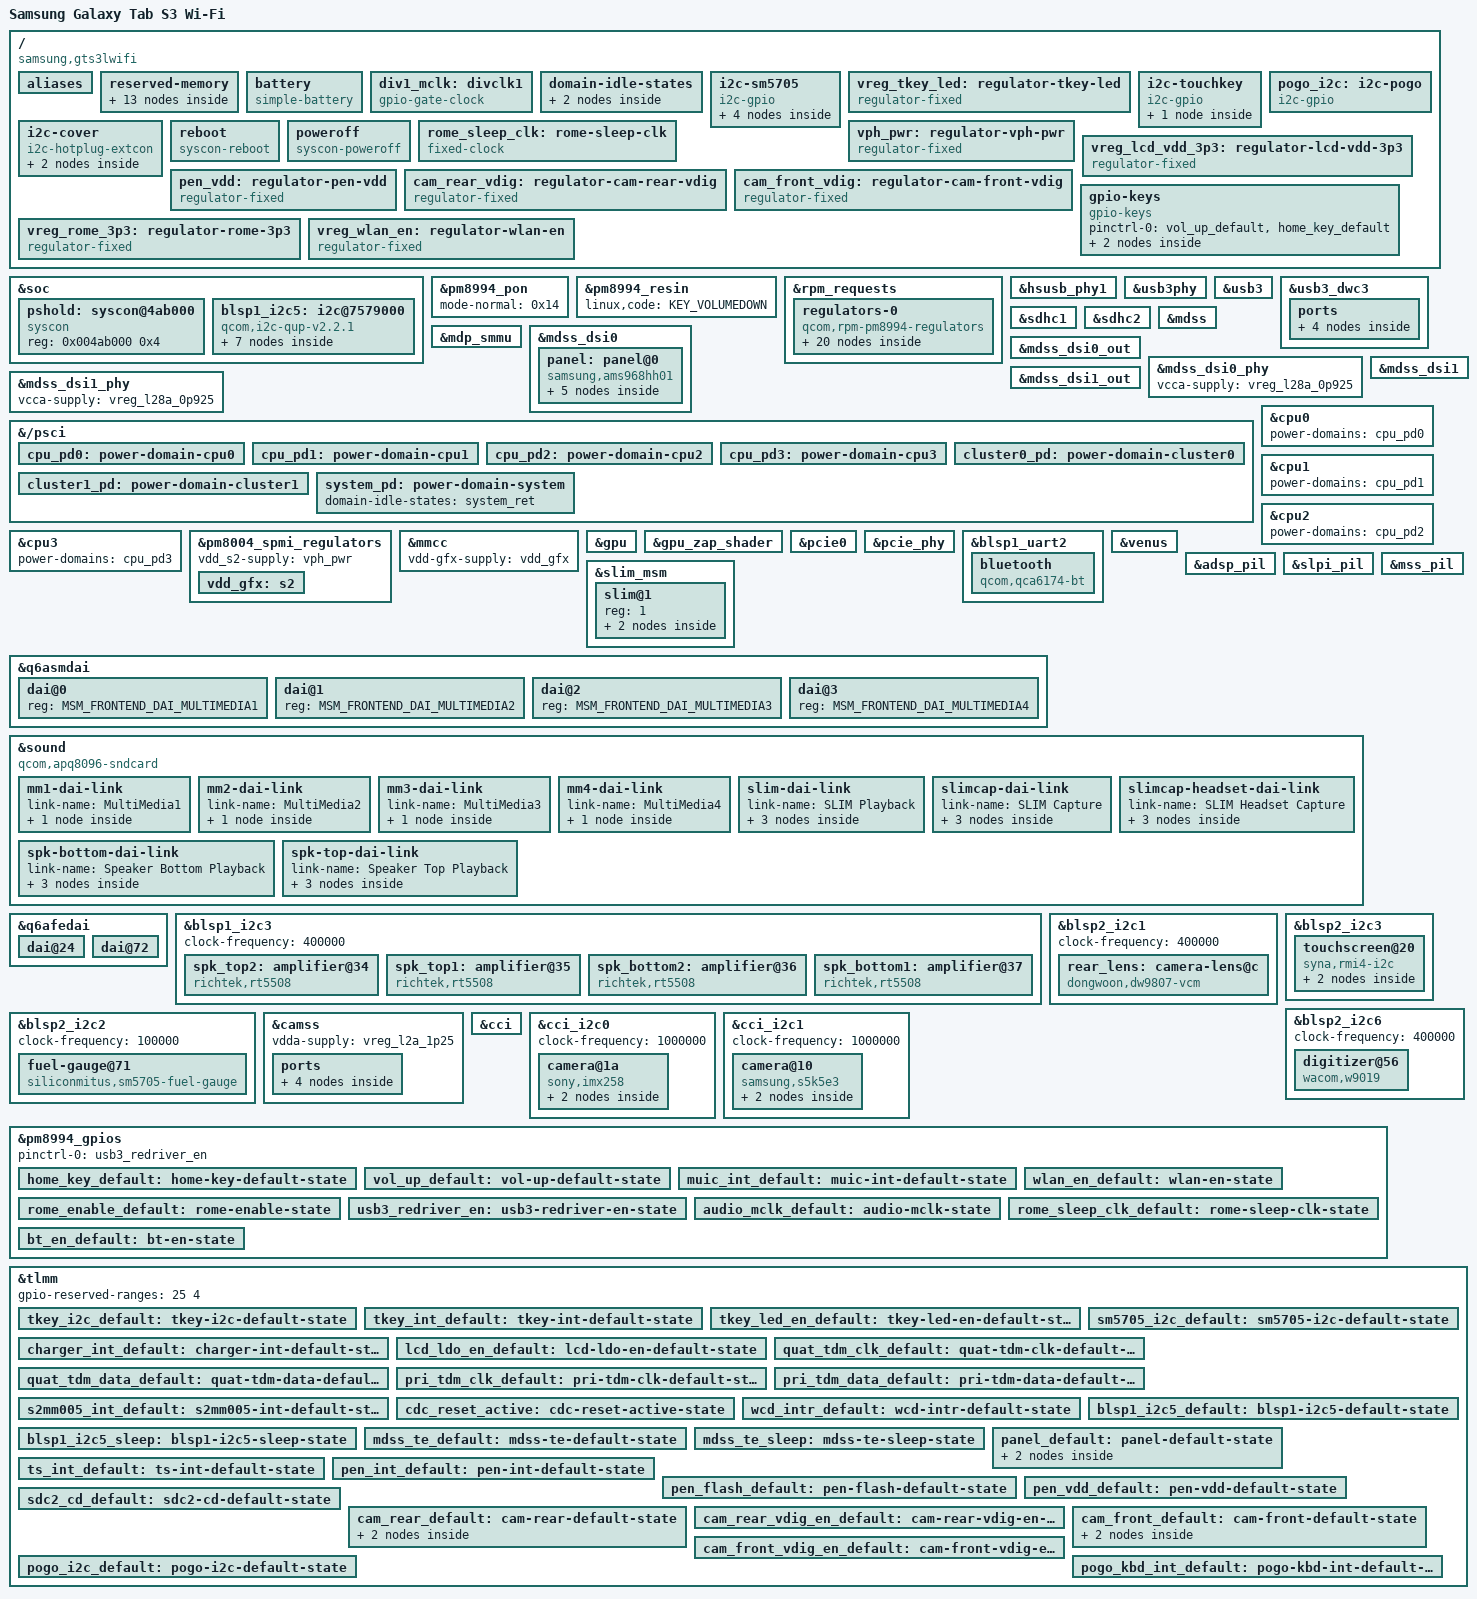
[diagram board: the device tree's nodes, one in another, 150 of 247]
// SPDX-License-Identifier: BSD-3-Clause
/*
 * Samsung Galaxy Tab S3 Wi-Fi (SM-T820), codename gts3lwifi, board rev 05
 *
 * SoC / PMIC set, from the live downstream DTB (qcom,pmic-id = <0x20009 0x1000c>):
 *   APQ8096 (msm-id 291) + PM8994 + PM8004. No PMI8994. No cellular modem,
 *   but the modem DSP is there and runs a GNSS-only image.
 * Internal storage: eMMC on SDHC1 (cmdline: androidboot.bootdevice=7464900.sdhci).
 *   UFS silicon is present but unpopulated; ufshc/ufsphy stay disabled.
 *
 * Working: eMMC, microSD, USB peripheral, host and OTG (USB 3.0), reboot
 * and power-off, display (AMS968HH01 dual-DSI command-mode panel), GPU,
 * touch, S-Pen, Volume and Home keys, Wi-Fi and Bluetooth (QCA6174), Venus,
 * audio (ADSP + WCD9335: headphones and microphones; four RT5508 speaker
 * amplifiers), SM5705 fuel gauge, charger, MUIC and flash LED (torch),
 * S2MM005 USB Type-C/PD (sink up to 9 V, source), accelerometer, gyroscope
 * and magnetometer (through the SLPI sensor core), CPU/cluster/system idle,
 * both cameras, the Book Cover Keyboard (hot-plugged through the MUIC),
 * GNSS (on the modem DSP). The panel's temperature input has a test DT; the
 * cover's hall sensor is not here yet.
 *
 * GPU zap shader, Venus, ADSP, SLPI and modem DSP firmware are
 * Samsung-signed and come from the device (apnhlos and modem partitions),
 * under
 * qcom/msm8996/samsung/gts3/; the device package's gts3-firmware copies
 * them, and the sensor registry from the efs partition, on first boot.
 *
 * The LTE model (SM-T825) uses this file too: msm8996-samsung-gts3llte.dts
 * includes it and changes the SoC ID, the modem memory and the pins it may
 * not touch. One kernel and one device package boot both models.
 *
 * Sources (all cross-checked against the live DTB with phandles resolved):
 *   downstream arch/arm64/boot/dts/samsung/msm8996-sec-gts3lwifi-r05.dts{,i}
 *   downstream arch/arm64/boot/dts/samsung/msm8996-pinctrl-sec-gts3lwifi-r05.dtsi
 *   downstream arch/arm64/boot/dts/samsung/msm8996-sec-common.dtsi
 *   downstream arch/arm64/boot/dts/samsung/msm8996-sm5705.dtsi
 *   downstream arch/arm64/boot/dts/qcom/msm8996-pm.dtsi (idle StateIDs)
 */

/dts-v1/;

#include <dt-bindings/clock/qcom,dsi-phy-28nm.h>
#include <dt-bindings/gpio/gpio.h>
#include <dt-bindings/input/input.h>
#include <dt-bindings/interrupt-controller/irq.h>
#include <dt-bindings/leds/common.h>
#include <dt-bindings/pinctrl/qcom,pmic-gpio.h>
#include <dt-bindings/sound/qcom,q6afe.h>
#include <dt-bindings/sound/qcom,q6asm.h>
#include <dt-bindings/sound/qcom,wcd9335.h>
#include <dt-bindings/usb/pd.h>
#include "msm8996.dtsi"
#include "pm8994.dtsi"
#include "pm8004.dtsi"

/*
 * The firmware regions get the stock SM-T820 layout (reserved-memory
 * below): the modem image needs the whole stock modem carve-out, which is
 * larger than msm8996.dtsi's mpss_mem, so the regions after it move.
 */
/delete-node/ &mpss_mem;
/delete-node/ &slpi_mem;
/delete-node/ &adsp_mem;
/delete-node/ &gpu_mem;
/delete-node/ &venus_mem;
/delete-node/ &mba_mem;

/ {
	model = "Samsung Galaxy Tab S3 Wi-Fi";
	compatible = "samsung,gts3lwifi", "qcom,apq8096";
	chassis-type = "tablet";

	/*
	 * DTB-selection IDs (documented in arm/qcom.yaml). lk2nd, like the
	 * stock bootloader, picks the appended DTB whose msm-id and board-id
	 * match the tablet: msm-id 291 (APQ8096) is the SM-T820, 246 (MSM8996)
	 * the SM-T825 (msm8996-samsung-gts3llte.dts). Stock ships one DT per
	 * board revision, Rev00/02/04/05 as board-id <8 0>, <8 2>, <8 4>,
	 * <8 5>; list them all, or lk2nd finds no match on a tablet of another
	 * revision and refuses the image ("dtb not found").
	 */
	qcom,msm-id = <291 0x30001>;
	qcom,board-id = <8 0>, <8 2>, <8 4>, <8 5>;

	aliases {
		mmc0 = &sdhc1;
		mmc1 = &sdhc2;
	};

	/*
	 * No memory@ node on purpose: msm8996.dtsi carries the placeholder
	 * and lk2nd rewrites it from the DDR partition table. The live DTB
	 * shows 0x80000000 + 2 GiB and 0x100000000 + 0x7e5e0000, i.e. 4 GiB
	 * with a hole - hardcoding a flat 4 GiB at 0x80000000 overshoots.
	 */

	/*
	 * Fixed regions from the downstream tree that msm8996.dtsi does not
	 * already cover, and the firmware regions with the stock layout.
	 * hyp/xbl/smem/tz (0x85800000-0x88800000) in msm8996.dtsi are subsets
	 * of the downstream removed carve-out, so they are kept as they are.
	 */
	reserved-memory {
		/* Downstream ss_plog@84700000 */
		memory@84700000 {
			reg = <0x0 0x84700000 0x0 0x400000>;
			no-map;
		};

		/* Same slot and layout as downstream ramoops@84B00000 */
		ramoops@84b00000 {
			compatible = "ramoops";
			reg = <0x0 0x84b00000 0x0 0x100000>;
			record-size = <0x40000>;
			console-size = <0x40000>;
			ftrace-size = <0x40000>;
			pmsg-size = <0x40000>;
		};

		/* Downstream lk_region@0 */
		memory@84c00000 {
			reg = <0x0 0x84c00000 0x0 0x400000>;
			no-map;
		};

		/*
		 * Samsung sec_debug: sec_dbg=0x1ff000@0x85000000 and
		 * sec_log=0x200000@0x85200000 on the downstream cmdline.
		 * S-Boot reads this back in upload mode, keep it untouched.
		 */
		memory@85000000 {
			reg = <0x0 0x85000000 0x0 0x400000>;
			no-map;
		};

		/*
		 * Firmware regions, as the stock kernel places them on the
		 * SM-T820 (all of these images are relocatable). The modem
		 * image spans 0x6c00000 bytes from its lowest segment to the end
		 * of its last: the downstream modem_mem carve-out
		 * (msm8996-sec-common.dtsi), where stock loads it.
		 * qcom_q6v5_mss refuses a segment that ends past mpss_mem, and
		 * msm8996.dtsi's is 0x6200000. SLPI, ADSP (its segments span
		 * 0x2100000 bytes), the A530 zap shader and Venus then fill the
		 * downstream peripheral_region (0x8f400000-0x92500000), and the
		 * MBA, which stock allocates dynamically, goes right after it.
		 */
		mpss_mem: mpss@88800000 {
			reg = <0x0 0x88800000 0x0 0x6c00000>;
			no-map;
		};

		slpi_mem: slpi@8f400000 {
			reg = <0x0 0x8f400000 0x0 0xa00000>;
			no-map;
		};

		adsp_mem: adsp@8fe00000 {
			reg = <0x0 0x8fe00000 0x0 0x2100000>;
			no-map;
		};

		gpu_mem: gpu@91f00000 {
			compatible = "shared-dma-pool";
			reg = <0x0 0x91f00000 0x0 0x100000>;
			no-map;
		};

		venus_mem: venus@92000000 {
			reg = <0x0 0x92000000 0x0 0x500000>;
			no-map;
		};

		mba_mem: mba@92500000 {
			reg = <0x0 0x92500000 0x0 0x200000>;
			no-map;
		};

		/*
		 * The bootloader framebuffer (downstream cont_splash_mem,
		 * 0x9a400000, 28 MiB) is not reserved here: lk2nd adds its own
		 * reservation for it when lk2nd.pass-simplefb is used, and the
		 * two would overlap.
		 */

		/* Samsung TIMA (KNOX EL2), downstream tima_region@9C000000 */
		memory@9c000000 {
			reg = <0x0 0x9c000000 0x0 0x200000>;
			no-map;
		};

		/* Samsung RKP (KNOX EL2), downstream rkp_region@0x9C200000 */
		memory@9c200000 {
			reg = <0x0 0x9c200000 0x0 0xf00000>;
			no-map;
		};

		/* Pool handed to TrustZone, downstream qseecom_mem */
		memory@fec00000 {
			reg = <0x0 0xfec00000 0x0 0x1400000>;
			no-map;
		};
	};

	/*
	 * EB-BT825ABE, 6000 mAh, 3.85 V. Stock charges to 4.30 V
	 * (battery,chg_float_voltage), tops off at 300 mA, powers off
	 * around 3.4 V (battery0,tem_poff) and stops charging outside
	 * 0-50 C (battery,temp_{low,high}_threshold_normal).
	 */
	battery: battery {
		compatible = "simple-battery";
		device-chemistry = "lithium-ion";
		charge-full-design-microamp-hours = <6000000>;
		energy-full-design-microwatt-hours = <23100000>;
		voltage-min-design-microvolt = <3400000>;
		voltage-max-design-microvolt = <4300000>;
		constant-charge-voltage-max-microvolt = <4300000>;
		charge-term-current-microamp = <300000>;
		alert-celsius = <0 50>;
	};

	/* WCD9335 MCLK, 9.6 MHz: RPM div_clk1 out on PM8994 GPIO 15 */
	div1_mclk: divclk1 {
		compatible = "gpio-gate-clock";
		clocks = <&rpmcc RPM_SMD_DIV_CLK1>;
		#clock-cells = <0>;
		enable-gpios = <&pm8994_gpios 15 GPIO_ACTIVE_HIGH>;
		pinctrl-names = "default";
		pinctrl-0 = <&audio_mclk_default>;
	};

	/*
	 * Cluster and system idle, used through the PSCI power domains
	 * below. The firmware composes StateIDs the OSI way, like the
	 * downstream lpm-levels: power-down bit 30, affinity level at bit
	 * 24, system mode at bit 8, cluster mode at bit 4, CPU mode at bit 0.
	 * It grants L2 GDHS and system retention to the last CPU going down,
	 * with the CPUs in mode 4 without the power-down bit. It refuses the
	 * CPU power-down state (0x40000004, NOT_SUPPORTED), and with it L2
	 * power collapse (0x41000044, always DENIED). Latencies are on the
	 * safe side; downstream lists 90 and 350 us.
	 */
	domain-idle-states {
		cluster_gdhs: cluster-gdhs {
			compatible = "domain-idle-state";
			arm,psci-suspend-param = <0x01000034>;
			entry-latency-us = <200>;
			exit-latency-us = <300>;
			min-residency-us = <1000>;
		};

		system_ret: system-ret {
			compatible = "domain-idle-state";
			arm,psci-suspend-param = <0x02002334>;
			entry-latency-us = <400>;
			exit-latency-us = <700>;
			min-residency-us = <3000>;
		};
	};

	/*
	 * SM5705 charger and MUIC. Downstream bit-bangs this bus on TLMM 33
	 * (SDA) / 32 (SCL), which are HDMI DDC pins, not a BLSP pair. The
	 * fuel gauge of the same chip is on its own bus, see &blsp2_i2c2.
	 */
	i2c-sm5705 {
		compatible = "i2c-gpio";
		sda-gpios = <&tlmm 33 (GPIO_ACTIVE_HIGH | GPIO_OPEN_DRAIN)>;
		scl-gpios = <&tlmm 32 (GPIO_ACTIVE_HIGH | GPIO_OPEN_DRAIN)>;
		i2c-gpio,delay-us = <2>;
		pinctrl-names = "default";
		pinctrl-0 = <&sm5705_i2c_default>;
		#address-cells = <1>;
		#size-cells = <0>;

		/* USB charger type (BC1.2) */
		muic: extcon@25 {
			compatible = "siliconmitus,sm5705-muic";
			reg = <0x25>;
			interrupts-extended = <&pm8994_gpios 4 IRQ_TYPE_LEVEL_LOW>;
			pinctrl-names = "default";
			pinctrl-0 = <&muic_int_default>;
		};

		/*
		 * Charger and flash LED. Charging enable is PM8994 GPIO 13,
		 * active low; the bootloader leaves it low. Without a driver
		 * the charger keeps a 4.38 V charge voltage; the driver applies
		 * the battery's 4.30 V.
		 */
		charger: charger@49 {
			compatible = "siliconmitus,sm5705-charger";
			reg = <0x49>;
			interrupts-extended = <&tlmm 38 IRQ_TYPE_LEVEL_LOW>;
			pinctrl-names = "default";
			pinctrl-0 = <&charger_int_default>;
			monitored-battery = <&battery>;
			extcon = <&muic>;
			power-supplies = <&typec>;

			/*
			 * Rear camera flash on FLED1, as a torch over I2C. Stock
			 * drives it through TLMM 11 (torch) / 12 (flash) instead;
			 * they stay low. 180 mA is stock's camera torch current.
			 */
			led {
				function = LED_FUNCTION_TORCH;
				color = <LED_COLOR_ID_WHITE>;
				led-max-microamp = <180000>;
			};

			/* the boost onto VBUS, for USB OTG */
			otg_vbus: usb-otg-vbus {
				regulator-name = "usb_otg_vbus";
			};
		};
	};

	/*
	 * Recent and Back keys (downstream i2c@22, tc305k@20): the controller
	 * runs from L19, and TLMM 118 switches the supply of the key LEDs.
	 */
	vreg_tkey_led: regulator-tkey-led {
		compatible = "regulator-fixed";
		regulator-name = "vreg_tkey_led";
		gpio = <&tlmm 118 GPIO_ACTIVE_HIGH>;
		enable-active-high;
		pinctrl-0 = <&tkey_led_en_default>;
		pinctrl-names = "default";
	};

	i2c-touchkey {
		compatible = "i2c-gpio";
		sda-gpios = <&tlmm 21 (GPIO_ACTIVE_HIGH | GPIO_OPEN_DRAIN)>;
		scl-gpios = <&tlmm 22 (GPIO_ACTIVE_HIGH | GPIO_OPEN_DRAIN)>;
		pinctrl-0 = <&tkey_i2c_default>;
		pinctrl-names = "default";
		#address-cells = <1>;
		#size-cells = <0>;

		touchkey@20 {
			compatible = "coreriver,tc305k-touchkey";
			reg = <0x20>;
			interrupts-extended = <&tlmm 64 IRQ_TYPE_LEVEL_LOW>;
			vcc-supply = <&vreg_l19a_2p2>;
			vdd-supply = <&vreg_tkey_led>;
			linux,keycodes = <KEY_APPSELECT KEY_BACK>;
			pinctrl-0 = <&tkey_int_default>;
			pinctrl-names = "default";
		};
	};

	/* Book Cover Keyboard (EJ-FT820) on the pogo pins */
	pogo_i2c: i2c-pogo {
		compatible = "i2c-gpio";
		sda-gpios = <&tlmm 2 (GPIO_ACTIVE_HIGH | GPIO_OPEN_DRAIN)>;
		scl-gpios = <&tlmm 3 (GPIO_ACTIVE_HIGH | GPIO_OPEN_DRAIN)>;
		i2c-gpio,delay-us = <2>;
		pinctrl-0 = <&pogo_i2c_default>;
		pinctrl-names = "default";
		#address-cells = <1>;
		#size-cells = <0>;
	};

	/*
	 * The keyboard's controller is only there while the cover is
	 * attached, which the MUIC reports as a dock (49.9 kOhm on the ID
	 * pin, ADC_KEYBOARDDOCK in Samsung's muic.h).
	 */
	i2c-cover {
		compatible = "i2c-hotplug-extcon";
		extcon = <&muic>;
		i2c-parent = <&pogo_i2c>;
		#address-cells = <1>;
		#size-cells = <0>;

		keyboard@40 {
			compatible = "st,stmpe1801";
			reg = <0x40>;
			/* stmpe_probe() only looks for "interrupts" */
			interrupt-parent = <&tlmm>;
			interrupts = <54 IRQ_TYPE_LEVEL_LOW>;
			pinctrl-0 = <&pogo_kbd_int_default>;
			pinctrl-names = "default";
			vcc-supply = <&vreg_l6a_1p8>;
			/* a key press wakes the tablet, while the cover is on */
			wakeup-source;

			keyboard-controller {
				compatible = "st,stmpe-keypad";
				debounce-interval = <10>;
				st,scan-count = <3>;
				keypad,num-rows = <8>;
				keypad,num-columns = <10>;
				linux,keymap = <
					MATRIX_KEY(0, 2, KEY_Z)
					MATRIX_KEY(0, 3, KEY_102ND)
					MATRIX_KEY(0, 4, KEY_V)
					MATRIX_KEY(0, 5, KEY_M)
					MATRIX_KEY(0, 6, KEY_DOWN)
					MATRIX_KEY(0, 8, KEY_SPACE)
					MATRIX_KEY(0, 9, KEY_UP)
					MATRIX_KEY(1, 0, KEY_ONSCREEN_KEYBOARD)
					MATRIX_KEY(1, 1, KEY_LEFTMETA)
					MATRIX_KEY(1, 2, KEY_A)
					MATRIX_KEY(1, 3, KEY_X)
					MATRIX_KEY(1, 4, KEY_B)
					MATRIX_KEY(1, 5, KEY_N)
					MATRIX_KEY(1, 6, KEY_COMMA)
					MATRIX_KEY(1, 7, KEY_DOT)
					MATRIX_KEY(1, 8, KEY_SLASH)
					MATRIX_KEY(1, 9, KEY_RIGHTBRACE)
					MATRIX_KEY(2, 1, KEY_HANGEUL)
					MATRIX_KEY(2, 2, KEY_Q)
					MATRIX_KEY(2, 3, KEY_S)
					MATRIX_KEY(2, 4, KEY_F)
					MATRIX_KEY(2, 5, KEY_J)
					MATRIX_KEY(2, 6, KEY_K)
					MATRIX_KEY(2, 7, KEY_L)
					MATRIX_KEY(2, 8, KEY_SEMICOLON)
					MATRIX_KEY(2, 9, KEY_ENTER)
					MATRIX_KEY(3, 1, KEY_LEFTALT)
					MATRIX_KEY(3, 2, KEY_TAB)
					MATRIX_KEY(3, 3, KEY_W)
					MATRIX_KEY(3, 4, KEY_G)
					MATRIX_KEY(3, 5, KEY_H)
					MATRIX_KEY(3, 6, KEY_I)
					MATRIX_KEY(3, 7, KEY_APOSTROPHE)
					MATRIX_KEY(3, 8, KEY_P)
					MATRIX_KEY(3, 9, KEY_BACKSLASH)
					MATRIX_KEY(4, 0, KEY_CAPSLOCK)
					MATRIX_KEY(4, 1, KEY_RIGHTALT)
					MATRIX_KEY(4, 2, KEY_1)
					MATRIX_KEY(4, 3, KEY_2)
					MATRIX_KEY(4, 4, KEY_R)
					MATRIX_KEY(4, 5, KEY_U)
					MATRIX_KEY(4, 6, KEY_8)
					MATRIX_KEY(4, 7, KEY_O)
					MATRIX_KEY(4, 8, KEY_0)
					MATRIX_KEY(4, 9, KEY_BACKSLASH)
					MATRIX_KEY(5, 1, KEY_LEFTCTRL)
					MATRIX_KEY(5, 2, KEY_GRAVE)
					MATRIX_KEY(5, 3, KEY_RIGHT)
					MATRIX_KEY(5, 4, KEY_T)
					MATRIX_KEY(5, 5, KEY_Y)
					MATRIX_KEY(5, 7, KEY_LEFTBRACE)
					MATRIX_KEY(5, 8, KEY_BACKSPACE)
					MATRIX_KEY(5, 9, KEY_MINUS)
					MATRIX_KEY(6, 0, KEY_RIGHTSHIFT)
					MATRIX_KEY(6, 1, KEY_LEFT)
					MATRIX_KEY(6, 2, KEY_D)
					MATRIX_KEY(6, 3, KEY_C)
					MATRIX_KEY(6, 4, KEY_4)
					MATRIX_KEY(6, 5, KEY_7)
					MATRIX_KEY(6, 7, KEY_9)
					MATRIX_KEY(6, 8, KEY_3)
					MATRIX_KEY(6, 9, KEY_E)
					MATRIX_KEY(7, 0, KEY_LEFTSHIFT)
					MATRIX_KEY(7, 4, KEY_5)
					MATRIX_KEY(7, 6, KEY_6)
					MATRIX_KEY(7, 7, KEY_EQUAL)
				>;
			};
		};
	};

	/*
	 * Restart. Samsung's TrustZone never returns from PSCI SYSTEM_RESET:
	 * the CPU stays stuck in the call, and about a minute later a secure
	 * watchdog leaves the tablet in a state that needs a forced restart.
	 * The vendor kernel never uses PSCI for this; it drops PS_HOLD
	 * (MPM2 PS_HOLD, 0x004ab000 bit 0, writable from Linux) and the PMIC
	 * resets. syscon-reboot does the same and, at its default priority
	 * (192), runs before the PSCI handler (129). pm8941-pwrkey programs
	 * the PMIC PS_HOLD reset type (hard reset) on a normal reboot.
	 */
	reboot {
		compatible = "syscon-reboot";
		regmap = <&pshold>;
		offset = <0x0>;
		mask = <0x1>;
		value = <0x0>;
	};

	/*
	 * Power-off: PSCI SYSTEM_OFF returns without doing anything in
	 * Samsung's TrustZone, and the kernel then runs on with the other CPUs
	 * stopped. Drop PS_HOLD as for restart; pm8941-pwrkey has set the PMIC
	 * PS_HOLD reset type to shutdown by then. Runs after the PSCI handler.
	 */
	poweroff {
		compatible = "syscon-poweroff";
		regmap = <&pshold>;
		offset = <0x0>;
		mask = <0x1>;
		value = <0x0>;
	};

	/* QCA6174 sleep clock: PM8994 GPIO 18 function 2, see &pm8994_gpios */
	rome_sleep_clk: rome-sleep-clk {
		compatible = "fixed-clock";
		#clock-cells = <0>;
		clock-frequency = <32768>;
		clock-output-names = "rome_sleep_clk";
	};

	/* Battery / charger system rail, root of every PM8994 supply below */
	vph_pwr: regulator-vph-pwr {
		compatible = "regulator-fixed";
		regulator-name = "vph_pwr";
		regulator-min-microvolt = <3800000>;
		regulator-max-microvolt = <3800000>;
		regulator-always-on;
		regulator-boot-on;
	};

	/*
	 * SM57xx rails
	 * ------------
	 * None on this board feed USB, eMMC or the panel:
	 *  - SM5703 (msm8996-sm5703.dtsi) is only included by gts2llte,
	 *    never by any gts3lwifi/gts3llte revision.
	 *  - SM5705 (msm8996-sm5705.dtsi) is charger + MUIC + fuel gauge +
	 *    flash LED. The downstream defconfig does not set
	 *    CONFIG_REGULATOR_SM5705, no such driver exists in that tree,
	 *    and no *-supply anywhere resolves to an SM5705 node.
	 *  - USB PHYs: PM8994 L28 / L12 / L24. eMMC: PM8994 L20 / S4.
	 *    Panel VDD 3.3 V: external LDO gated by LCD_LDO_EN (TLMM 46),
	 *    modelled downstream as the fake regulator "ssreg-vdd".
	 * The only non-PMIC rail that therefore needs a stub is that LDO.
	 */
	vreg_lcd_vdd_3p3: regulator-lcd-vdd-3p3 {
		compatible = "regulator-fixed";
		regulator-name = "vreg_lcd_vdd_3p3";
		regulator-min-microvolt = <3300000>;
		regulator-max-microvolt = <3300000>;
		gpio = <&tlmm 46 GPIO_ACTIVE_HIGH>;
		enable-active-high;
		regulator-boot-on;
		regulator-always-on;
		vin-supply = <&vph_pwr>;
		pinctrl-names = "default";
		pinctrl-0 = <&lcd_ldo_en_default>;
	};

	/* S-Pen digitizer 3.3 V, a switch on TLMM 126 (downstream wacom@56) */
	pen_vdd: regulator-pen-vdd {
		compatible = "regulator-fixed";
		regulator-name = "pen_vdd_3p3";
		regulator-min-microvolt = <3300000>;
		regulator-max-microvolt = <3300000>;
		gpio = <&tlmm 126 GPIO_ACTIVE_HIGH>;
		enable-active-high;
		regulator-boot-on;
		pinctrl-names = "default";
		pinctrl-0 = <&pen_vdd_default>;
	};

	/*
	 * Camera core supplies: switched regulators fed from S3, enabled by
	 * CAM_CORE_EN (rear, TLMM 9) and CAM_VDIG (front, TLMM 8) in the
	 * downstream camera@0 and camera@2 nodes. Their output voltage is
	 * not documented downstream; 1.2 V is what both sensors take.
	 */
	cam_rear_vdig: regulator-cam-rear-vdig {
		compatible = "regulator-fixed";
		regulator-name = "cam_rear_vdig_1p2";
		regulator-min-microvolt = <1200000>;
		regulator-max-microvolt = <1200000>;
		gpio = <&tlmm 9 GPIO_ACTIVE_HIGH>;
		enable-active-high;
		startup-delay-us = <1000>;
		vin-supply = <&vreg_s3a_1p3>;
		pinctrl-names = "default";
		pinctrl-0 = <&cam_rear_vdig_en_default>;
	};

	cam_front_vdig: regulator-cam-front-vdig {
		compatible = "regulator-fixed";
		regulator-name = "cam_front_vdig_1p2";
		regulator-min-microvolt = <1200000>;
		regulator-max-microvolt = <1200000>;
		gpio = <&tlmm 8 GPIO_ACTIVE_HIGH>;
		enable-active-high;
		startup-delay-us = <1000>;
		vin-supply = <&vreg_s3a_1p3>;
		pinctrl-names = "default";
		pinctrl-0 = <&cam_front_vdig_en_default>;
	};

	/*
	 * Volume Up and Home (downstream gpio_keys in msm8996-sec-common.dtsi:
	 * PM8994 GPIO 3 and 2, active low, 15 ms debounce, Home a wakeup
	 * source). Volume Down is the PON RESIN input below, Power the PON
	 * power key. Home keeps the stock KEY_HOMEPAGE, as other Samsung DTs
	 * upstream do. The cover's hall sensor (stock hall_flip, PM8994
	 * GPIO 7) is left out until suspend is settled: logind suspends on
	 * SW_LID.
	 */
	gpio-keys {
		compatible = "gpio-keys";
		pinctrl-0 = <&vol_up_default>, <&home_key_default>;
		pinctrl-names = "default";

		key-volume-up {
			label = "Volume Up";
			gpios = <&pm8994_gpios 3 GPIO_ACTIVE_LOW>;
			linux,code = <KEY_VOLUMEUP>;
			debounce-interval = <15>;
		};

		key-home {
			label = "Home";
			gpios = <&pm8994_gpios 2 GPIO_ACTIVE_LOW>;
			linux,code = <KEY_HOMEPAGE>;
			wakeup-source;
			debounce-interval = <15>;
		};
	};

	/*
	 * QCA6174 ("Rome") Wi-Fi/BT power, from the downstream qcom,cnss
	 * node (cnss_wlan_en_vreg / rome_vreg), wired like the Xiaomi MSM8996
	 * boards: PM8994 GPIO 9 enables the 3.3 V supply, GPIO 8 is WLAN_EN.
	 *
	 * BT_EN (PM8994 GPIO 19) must be low while the 3.3 V rail comes up.
	 * The bootloader leaves it high; if the rail rises like that, Rome
	 * turns on its PCIe receiver after PERST# but never transmits (the
	 * root port sits in Polling.Compliance). So the 3.3 V regulator is
	 * not always-on: it starts off at probe, stays off for
	 * off-on-delay-us with BT_EN held low, and the PCIe driver switches
	 * it on through the WLAN_EN regulator.
	 */
	vreg_rome_3p3: regulator-rome-3p3 {
		compatible = "regulator-fixed";
		regulator-name = "vreg_rome_3p3";
		regulator-min-microvolt = <3300000>;
		regulator-max-microvolt = <3300000>;
		startup-delay-us = <4000>;
		off-on-delay-us = <1000000>;
		vin-supply = <&vph_pwr>;

		gpio = <&pm8994_gpios 9 GPIO_ACTIVE_HIGH>;
		enable-active-high;
		pinctrl-names = "default";
		pinctrl-0 = <&rome_enable_default>, <&bt_en_default>,
			    <&rome_sleep_clk_default>;
	};

	vreg_wlan_en: regulator-wlan-en {
		compatible = "regulator-fixed";
		regulator-name = "vreg_wlan_en";
		regulator-min-microvolt = <1800000>;
		regulator-max-microvolt = <1800000>;
		startup-delay-us = <70000>;
		vin-supply = <&vreg_rome_3p3>;

		gpio = <&pm8994_gpios 8 GPIO_ACTIVE_HIGH>;
		enable-active-high;
		pinctrl-names = "default";
		pinctrl-0 = <&wlan_en_default>;
	};
};

&soc {
	pshold: syscon@4ab000 {
		compatible = "syscon";
		reg = <0x004ab000 0x4>;
	};

	/*
	 * BLSP1 QUP5 I2C (TLMM 83 SDA, 84 SCL, downstream i2c_5), for the
	 * Type-C controller. msm8996.dtsi has no node for it; this one follows
	 * blsp1_i2c3/blsp1_i2c6 (QUP n: GIC SPI 94 + n, BAM channels 10 + 2n).
	 */
	blsp1_i2c5: i2c@7579000 {
		compatible = "qcom,i2c-qup-v2.2.1";
		reg = <0x07579000 0x1000>;
		interrupts = <GIC_SPI 99 IRQ_TYPE_LEVEL_HIGH>;
		clocks = <&gcc GCC_BLSP1_QUP5_I2C_APPS_CLK>,
			 <&gcc GCC_BLSP1_AHB_CLK>;
		clock-names = "core", "iface";
		pinctrl-names = "default", "sleep";
		pinctrl-0 = <&blsp1_i2c5_default>;
		pinctrl-1 = <&blsp1_i2c5_sleep>;
		dmas = <&blsp1_dma 20>, <&blsp1_dma 21>;
		dma-names = "tx", "rx";
		clock-frequency = <100000>;
		#address-cells = <1>;
		#size-cells = <0>;

		/*
		 * Samsung S2MM005 USB Type-C and PD controller. Its firmware
		 * negotiates the PD contract by itself; the charger takes its
		 * input limit from this supply too. As a source it needs the
		 * charger's boost for VBUS. Interrupt: open drain, low while
		 * an event is pending, pulled up on the board.
		 */
		typec: typec@33 {
			compatible = "samsung,s2mm005";
			reg = <0x33>;
			interrupts-extended = <&tlmm 73 IRQ_TYPE_LEVEL_LOW>;
			pinctrl-0 = <&s2mm005_int_default>;
			pinctrl-names = "default";

			connector {
				compatible = "usb-c-connector";
				label = "USB-C";
				power-role = "dual";
				data-role = "dual";
				vbus-supply = <&otg_vbus>;
				/*
				 * 5 V, or 9 V at the input limit Samsung uses
				 * for its 15 W chargers
				 */
				sink-pdos = <PDO_FIXED(5000, 3000,
						       PDO_FIXED_DUAL_ROLE |
						       PDO_FIXED_USB_COMM |
						       PDO_FIXED_DATA_SWAP)
					     PDO_FIXED(9000, 1650, 0)>;
				op-sink-microwatt = <15000000>;

				ports {
					#address-cells = <1>;
					#size-cells = <0>;

					port@0 {
						reg = <0>;

						typec_hs: endpoint {
							remote-endpoint = <&usb3_dwc3_hs>;
						};
					};

					port@1 {
						reg = <1>;

						typec_ss: endpoint {
							remote-endpoint = <&usb3_dwc3_ss>;
						};
					};
				};
			};
		};
	};
};

/*
 * Restart reasons as Samsung's bootloader reads them (vendor
 * PON_RESTART_REASON_*, stored in the PON spare register shifted by 2).
 * bootloader (0x02) and recovery (0x01) already match pm8994.dtsi;
 * NORMALBOOT (0x14) is what the vendor kernel writes on a plain reboot.
 */
&pm8994_pon {
	mode-normal = <0x14>;
};

/* Volume Down (downstream qcom,pon_2) */
&pm8994_resin {
	linux,code = <KEY_VOLUMEDOWN>;
	status = "okay";
};

/*
 * PM8994 rails via RPM. Only the rails consumed below are declared; the
 * parent-supply map follows apq8096-db820c.dts (PM8994 + no PMI8994 boost
 * bypass here, so the battery-fed LDO groups hang off vph_pwr directly).
 * Voltages match the downstream msm8996-regulator.dtsi / live DTB.
 */
&rpm_requests {
	regulators-0 {
		compatible = "qcom,rpm-pm8994-regulators";

		vdd_s1-supply = <&vph_pwr>;
		vdd_s2-supply = <&vph_pwr>;
		vdd_s3-supply = <&vph_pwr>;
		vdd_s4-supply = <&vph_pwr>;
		vdd_s5-supply = <&vph_pwr>;
		vdd_s6-supply = <&vph_pwr>;
		vdd_s7-supply = <&vph_pwr>;
		vdd_s8-supply = <&vph_pwr>;
		vdd_s9-supply = <&vph_pwr>;
		vdd_s10-supply = <&vph_pwr>;
		vdd_s11-supply = <&vph_pwr>;
		vdd_s12-supply = <&vph_pwr>;
		vdd_l2_l26_l28-supply = <&vreg_s3a_1p3>;
		vdd_l6_l12_l32-supply = <&vreg_s5a_2p15>;
		vdd_l8_l16_l30-supply = <&vph_pwr>;
		vdd_l9_l10_l18_l22-supply = <&vph_pwr>;
		vdd_l13_l19_l23_l24-supply = <&vph_pwr>;
		vdd_l14_l15-supply = <&vreg_s5a_2p15>;
		vdd_l17_l29-supply = <&vph_pwr>;
		vdd_l20_l21-supply = <&vph_pwr>;
		vdd_lvs1_2-supply = <&vreg_s4a_1p8>;

		/* Also the QCA6174 1.3 V core, which ath10k does not manage */
		vreg_s3a_1p3: s3 {
			regulator-name = "vreg_s3a_1p3";
			regulator-min-microvolt = <1300000>;
			regulator-max-microvolt = <1300000>;
			regulator-always-on;
		};

		/*
		 * eMMC I/O rail; downstream marks it qcom,vdd-io-always-on.
		 * Also the WCD9335 and QCA6174 I/O supply.
		 */
		vreg_s4a_1p8: s4 {
			regulator-name = "vreg_s4a_1p8";
			regulator-min-microvolt = <1800000>;
			regulator-max-microvolt = <1800000>;
			regulator-always-on;
		};

		vreg_s5a_2p15: s5 {
			regulator-name = "vreg_s5a_2p15";
			regulator-min-microvolt = <2150000>;
			regulator-max-microvolt = <2150000>;
		};

		/* Camera I/O: both sensors, the rear lens driver */
		vreg_lvs1a_1p8: lvs1 {
			regulator-name = "vreg_lvs1a_1p8";
			regulator-min-microvolt = <1800000>;
			regulator-max-microvolt = <1800000>;
		};

		/*
		 * SSC pad supply (SLPI px) and the sensors' vdd/vddio; stock
		 * keeps it on (msm8996-sec-common.dtsi).
		 */
		vreg_lvs2a_1p8: lvs2 {
			regulator-name = "vreg_lvs2a_1p8";
			regulator-min-microvolt = <1800000>;
			regulator-max-microvolt = <1800000>;
			regulator-always-on;
		};

		/* DSI controller analog (msm8996 "vdda") */
		vreg_l2a_1p25: l2 {
			regulator-name = "vreg_l2a_1p25";
			regulator-min-microvolt = <1250000>;
			regulator-max-microvolt = <1250000>;
			regulator-allow-set-load;
		};

		/*
		 * Book Cover Keyboard (downstream pm8994_l6, "vdd" of the pogo
		 * keyboard). The keyboard's controller did not answer 10 ms
		 * after power-up; stock retries each transfer 3 times 10 ms
		 * apart (stmpe1801_pogo_keyboard.c).
		 */
		vreg_l6a_1p8: l6 {
			regulator-name = "vreg_l6a_1p8";
			regulator-min-microvolt = <1800000>;
			regulator-max-microvolt = <1800000>;
			regulator-enable-ramp-delay = <100000>;
		};

		/* USB PHY PLL / core 1.8 V (downstream vdda18 / core-supply) */
		vreg_l12a_1p8: l12 {
			regulator-name = "vreg_l12a_1p8";
			regulator-min-microvolt = <1800000>;
			regulator-max-microvolt = <1800000>;
			regulator-allow-set-load;
		};

		/* microSD I/O, 1.8-2.95 V (downstream sdhc_2 vdd-io) */
		vreg_l13a_2p95: l13 {
			regulator-name = "vreg_l13a_2p95";
			regulator-min-microvolt = <1800000>;
			regulator-max-microvolt = <2950000>;
			regulator-allow-set-load;
			regulator-system-load = <22000>;
		};

		/* DSI controller I/O (msm8996 "vddio"), touch controller I/O */
		vreg_l14a_1p8: l14 {
			regulator-name = "vreg_l14a_1p8";
			regulator-min-microvolt = <1800000>;
			regulator-max-microvolt = <1800000>;
			regulator-allow-set-load;
		};

		/* Rear camera lens driver (downstream cam_vaf) */
		vreg_l17a_2p8: l17 {
			regulator-name = "vreg_l17a_2p8";
			regulator-min-microvolt = <2800000>;
			regulator-max-microvolt = <2800000>;
		};

		/*
		 * 3.3 V on this board (downstream overrides msm8996's 2.7-2.9 V):
		 * touch controller analog supply (tsp_avdd), also requested by
		 * the downstream cnss node for the Wi-Fi antenna switch.
		 */
		vreg_l18a_3p3: l18 {
			regulator-name = "vreg_l18a_3p3";
			regulator-min-microvolt = <3300000>;
			regulator-max-microvolt = <3300000>;
			regulator-always-on;
		};

		/* Touch key controller */
		vreg_l19a_2p2: l19 {
			regulator-name = "vreg_l19a_2p2";
			regulator-min-microvolt = <2200000>;
			regulator-max-microvolt = <2200000>;
		};

		/* eMMC flash rail; downstream marks it qcom,vdd-always-on */
		vreg_l20a_2p95: l20 {
			regulator-name = "vreg_l20a_2p95";
			regulator-min-microvolt = <2950000>;
			regulator-max-microvolt = <2950000>;
			regulator-allow-set-load;
			regulator-always-on;
		};

		/* microSD card supply (downstream sdhc_2 vdd, up to 800 mA) */
		vreg_l21a_2p95: l21 {
			regulator-name = "vreg_l21a_2p95";
			regulator-min-microvolt = <2950000>;
			regulator-max-microvolt = <2950000>;
			regulator-allow-set-load;
			regulator-system-load = <800000>;
		};

		/* Front camera analog (downstream camera@2 cam_vana) */
		vreg_l23a_2p8: l23 {
			regulator-name = "vreg_l23a_2p8";
			regulator-min-microvolt = <2800000>;
			regulator-max-microvolt = <2800000>;
		};

		/* USB2 PHY D+/D- 3.075 V (downstream vdda33) */
		vreg_l24a_3p075: l24 {
			regulator-name = "vreg_l24a_3p075";
			regulator-min-microvolt = <3075000>;
			regulator-max-microvolt = <3075000>;
		};

		/* USB PHY digital 0.925 V (downstream vdd-supply on both PHYs) */
		vreg_l28a_0p925: l28 {
			regulator-name = "vreg_l28a_0p925";
			regulator-min-microvolt = <925000>;
			regulator-max-microvolt = <925000>;
			regulator-allow-set-load;
		};

		/* Rear camera analog (downstream camera@0 cam_vana) */
		vreg_l29a_2p8: l29 {
			regulator-name = "vreg_l29a_2p8";
			regulator-min-microvolt = <2800000>;
			regulator-max-microvolt = <2800000>;
		};

		/* QCA6174 crystal 1.8 V, not managed by ath10k */
		vreg_l30a_1p8: l30 {
			regulator-name = "vreg_l30a_1p8";
			regulator-min-microvolt = <1800000>;
			regulator-max-microvolt = <1800000>;
			regulator-always-on;
		};
	};
};

/*
 * USB
 * ---
 * Downstream: ssusb@6a00000 + dwc3@6a00000, maximum-speed "super-speed",
 * usb-phy = <qusb@7411000 ssphy@7410000>. The mainline equivalents are
 * usb3 (qcom,msm8996-dwc3) + usb3_dwc3, hsusb_phy1 (QUSB2, 0x7411000) and
 * usb3phy (QMP, 0x7410000).
 *
 * The SuperSpeed lanes pass a redriver enabled by PM8994 GPIO 14
 * (downstream usb-notifier qcom,gpios_redriver_en). The s2mm005 firmware
 * picks the lane pair for the plug orientation by itself, so the AP has
 * nothing to switch. Samsung's kernel enables the redriver only while
 * something is attached; here it stays on, see &pm8994_gpios.
 *
 * TLMM: the downstream USB nodes reference no TLMM pinctrl state at all,
 * and the mainline usb3/PHY nodes need none, so there is nothing to add.
 *
 * On v6.19 msm8996.dtsi still uses the child-node form, which binds to
 * dwc3-qcom-legacy.c. That glue reads dr_mode from the child node and
 * forces the VBUS-valid override for every non-host mode, so no extcon is
 * needed to enumerate as a gadget. The s2mm005 drives the dwc3 role switch:
 * host when its firmware is the DFP (a sink on the port, or a hub that
 * swapped data roles), device otherwise. Without a role, and before the
 * s2mm005 driver loads, the core stays a peripheral.
 */
&hsusb_phy1 {
	vdd-supply = <&vreg_l28a_0p925>;
	vdda-pll-supply = <&vreg_l12a_1p8>;
	vdda-phy-dpdm-supply = <&vreg_l24a_3p075>;
	status = "okay";
};

&usb3phy {
	vdda-phy-supply = <&vreg_l28a_0p925>;
	vdda-pll-supply = <&vreg_l12a_1p8>;
	status = "okay";
};

&usb3 {
	status = "okay";
};

&usb3_dwc3 {
	dr_mode = "otg";
	usb-role-switch;
	snps,is-utmi-l1-suspend;
	snps,hird-threshold = /bits/ 8 <0>;
	snps,usb2-gadget-lpm-disable;

	ports {
		#address-cells = <1>;
		#size-cells = <0>;

		port@0 {
			reg = <0>;

			usb3_dwc3_hs: endpoint {
				remote-endpoint = <&typec_hs>;
			};
		};

		port@1 {
			reg = <1>;

			usb3_dwc3_ss: endpoint {
				remote-endpoint = <&typec_ss>;
			};
		};
	};
};

/*
 * eMMC (rootfs). Downstream sdhci@7464900: bus-width 8, HS400_1p8v /
 * HS200_1p8v / DDR_1p8v, vdd = PM8994 L20, vdd-io = PM8994 S4, both
 * always-on. sdc1_state_on / sdc1_state_off pinctrl comes from msm8996.dtsi.
 */
&sdhc1 {
	vmmc-supply = <&vreg_l20a_2p95>;
	vqmmc-supply = <&vreg_s4a_1p8>;
	mmc-hs400-1_8v;
	mmc-hs200-1_8v;
	status = "okay";
};

/*
 * microSD (downstream sdhc_2 in msm8996-mtp.dtsi, which the board DT
 * includes): vdd = PM8994 L21, vdd-io = PM8994 L13, card detect on TLMM 95,
 * active low, no internal pull. The bus pins are msm8996.dtsi's sdc2 states.
 */
&sdhc2 {
	pinctrl-names = "default", "sleep";
	pinctrl-0 = <&sdc2_state_on &sdc2_cd_default>;
	pinctrl-1 = <&sdc2_state_off &sdc2_cd_default>;
	cd-gpios = <&tlmm 95 GPIO_ACTIVE_LOW>;
	vmmc-supply = <&vreg_l21a_2p95>;
	vqmmc-supply = <&vreg_l13a_2p95>;
	status = "okay";
};

/*
 * Display
 * -------
 * AMS968HH01 AMOLED (Anapass ANA38401 DDI), 2048x1536, command mode over
 * two DSI links: DSI0 is the master, DSI1 the slave clocked from the DSI0
 * PHY, and MDP5 splits each frame between them. Panel VDD 3.3 V is the
 * LCD LDO above; reset TLMM 143, TCON_RDY TLMM 45, TE TLMM 10. The panel
 * is landscape in a portrait tablet: its left edge is the top, as with
 * the boot logo and stock Android (rotation 270).
 */
&mdss {
	status = "okay";
};

/* The msm DRM driver needs the MDSS IOMMU. */
&mdp_smmu {
	status = "okay";
};

&mdss_dsi0 {
	vdda-supply = <&vreg_l2a_1p25>;
	vcca-supply = <&vreg_l28a_0p925>;
	vddio-supply = <&vreg_l14a_1p8>;

	qcom,dual-dsi-mode;
	qcom,master-dsi;

	pinctrl-names = "default", "sleep";
	pinctrl-0 = <&mdss_te_default>;
	pinctrl-1 = <&mdss_te_sleep>;

	status = "okay";

	panel: panel@0 {
		compatible = "samsung,ams968hh01";
		reg = <0>;

		vdd-supply = <&vreg_lcd_vdd_3p3>;
		/* TLMM 143 high = panel running, so "active" (in reset) is low */
		reset-gpios = <&tlmm 143 GPIO_ACTIVE_LOW>;
		tcon-ready-gpios = <&tlmm 45 GPIO_ACTIVE_HIGH>;
		rotation = <270>;

		pinctrl-names = "default";
		pinctrl-0 = <&panel_default>;

		ports {
			#address-cells = <1>;
			#size-cells = <0>;

			port@0 {
				reg = <0>;
				panel_in0: endpoint {
					remote-endpoint = <&mdss_dsi0_out>;
				};
			};

			port@1 {
				reg = <1>;
				panel_in1: endpoint {
					remote-endpoint = <&mdss_dsi1_out>;
				};
			};
		};
	};
};

&mdss_dsi0_out {
	remote-endpoint = <&panel_in0>;
	data-lanes = <0 1 2 3>;
};

&mdss_dsi0_phy {
	vcca-supply = <&vreg_l28a_0p925>;
	status = "okay";
};

&mdss_dsi1 {
	vdda-supply = <&vreg_l2a_1p25>;
	vcca-supply = <&vreg_l28a_0p925>;
	vddio-supply = <&vreg_l14a_1p8>;

	qcom,dual-dsi-mode;
	/* DSI1 is the slave link, clock it from the DSI0 PHY */
	assigned-clock-parents = <&mdss_dsi0_phy DSI_BYTE_PLL_CLK>,
				 <&mdss_dsi0_phy DSI_PIXEL_PLL_CLK>;

	status = "okay";
};

&mdss_dsi1_out {
	remote-endpoint = <&panel_in1>;
	data-lanes = <0 1 2 3>;
};

&mdss_dsi1_phy {
	vcca-supply = <&vreg_l28a_0p925>;
	status = "okay";
};

/*
 * CPU idle
 * --------
 * Hierarchical PSCI layout: CPU -> cluster (CPU0-1, CPU2-3) -> system,
 * with the msm8996.dtsi CPU state (0x4) per CPU and the states in
 * /domain-idle-states above. The firmware is in OSI mode from boot but
 * answers NOT_SUPPORTED to PSCI SET_SUSPEND_MODE, which cpuidle-psci-domain
 * accepts on msm8996/apq8096; without that the CPUs get no idle states.
 */
&{/psci} {
	cpu_pd0: power-domain-cpu0 {
		#power-domain-cells = <0>;
		power-domains = <&cluster0_pd>;
		domain-idle-states = <&cpu_sleep_0>;
	};

	cpu_pd1: power-domain-cpu1 {
		#power-domain-cells = <0>;
		power-domains = <&cluster0_pd>;
		domain-idle-states = <&cpu_sleep_0>;
	};

	cpu_pd2: power-domain-cpu2 {
		#power-domain-cells = <0>;
		power-domains = <&cluster1_pd>;
		domain-idle-states = <&cpu_sleep_0>;
	};

	cpu_pd3: power-domain-cpu3 {
		#power-domain-cells = <0>;
		power-domains = <&cluster1_pd>;
		domain-idle-states = <&cpu_sleep_0>;
	};

	cluster0_pd: power-domain-cluster0 {
		#power-domain-cells = <0>;
		power-domains = <&system_pd>;
		domain-idle-states = <&cluster_gdhs>;
	};

	cluster1_pd: power-domain-cluster1 {
		#power-domain-cells = <0>;
		power-domains = <&system_pd>;
		domain-idle-states = <&cluster_gdhs>;
	};

	system_pd: power-domain-system {
		#power-domain-cells = <0>;
		domain-idle-states = <&system_ret>;
	};
};

&cpu0 {
	/delete-property/ cpu-idle-states;
	power-domains = <&cpu_pd0>;
	power-domain-names = "psci";
};

&cpu1 {
	/delete-property/ cpu-idle-states;
	power-domains = <&cpu_pd1>;
	power-domain-names = "psci";
};

&cpu2 {
	/delete-property/ cpu-idle-states;
	power-domains = <&cpu_pd2>;
	power-domain-names = "psci";
};

&cpu3 {
	/delete-property/ cpu-idle-states;
	power-domains = <&cpu_pd3>;
	power-domain-names = "psci";
};

/*
 * GPU
 * ---
 * Adreno 530, headless while the panel is off: boot with
 * msm.separate_gpu_kms=1 so it gets its own DRM device without MDSS.
 * VDD_GFX is PM8004 S2 (downstream 400-1015 mV under GFX CPR). Mainline
 * has no GFX CPR, so pin it at the top corner like the Sony msm8996 boards.
 */
&pm8004_spmi_regulators {
	vdd_s2-supply = <&vph_pwr>;

	vdd_gfx: s2 {
		regulator-name = "vdd_gfx";
		regulator-min-microvolt = <1015000>;
		regulator-max-microvolt = <1015000>;
		regulator-always-on;
	};
};

&mmcc {
	vdd-gfx-supply = <&vdd_gfx>;
};

&gpu {
	status = "okay";
};

&gpu_zap_shader {
	firmware-name = "qcom/msm8996/samsung/gts3/a530_zap.mdt";
};

/*
 * Wi-Fi: QCA6174 on PCIe0 (ath10k), PERST# TLMM 35, WAKE# TLMM 37.
 * The PCIe driver switches WLAN_EN, which pulls in the 3.3 V rail.
 */
&pcie0 {
	vddpe-3v3-supply = <&vreg_wlan_en>;
	vdda-supply = <&vreg_l28a_0p925>;

	perst-gpios = <&tlmm 35 GPIO_ACTIVE_LOW>;
	wake-gpios = <&tlmm 37 GPIO_ACTIVE_HIGH>;

	status = "okay";
};

&pcie_phy {
	vdda-phy-supply = <&vreg_l28a_0p925>;
	vdda-pll-supply = <&vreg_l12a_1p8>;

	status = "okay";
};

/* Bluetooth: QCA6174 on BLSP1 UART2 (TLMM 41-44), BT_EN PM8994 GPIO 19 */
&blsp1_uart2 {
	label = "BT-UART";
	uart-has-rtscts;
	status = "okay";

	bluetooth {
		compatible = "qcom,qca6174-bt";
		enable-gpios = <&pm8994_gpios 19 GPIO_ACTIVE_HIGH>;
		clocks = <&rome_sleep_clk>;
	};
};

/*
 * Video: Venus with Samsung's signed firmware (PAS id 9). Its relocatable
 * segments fit msm8996.dtsi's venus_mem.
 */
&venus {
	firmware-name = "qcom/msm8996/samsung/gts3/venus.mdt";
	status = "okay";
};

/*
 * Audio
 * -----
 * ADSP with Samsung's signed firmware from the modem partition. Its
 * segments span 0x2100000 bytes, more than msm8996.dtsi's adsp_mem; the
 * stock region (reserved-memory above) fits them.
 *
 * WCD9335 on SLIMbus like apq8096-db820c: reset TLMM 74, one interrupt line
 * on TLMM 79, MCLK from PM8994 GPIO 15, all supplies PM8994 S4. Headphones
 * play through SLIMBUS_6_RX, the microphones record through SLIMBUS_0_TX;
 * the routing is in the UCM profile.
 *
 * Speakers: four Richtek RT5508 amplifiers on BLSP1 QUP3 I2C (TLMM 47/48,
 * downstream i2c_3). The bottom pair (0x36/0x37, USB end) is on the primary
 * TDM bus (TLMM 65 SCK, 66 WS, 68 SD1), the top pair (0x34/0x35) on the
 * quaternary one (TLMM 58 SCK, 59 WS, 61 SD1). Both run 4 slots of 16 bit
 * at 48 kHz (3.072 MHz) with a long, inverted frame sync from the SoC and
 * one bit of data delay, like stock. One stream feeds both buses (q6routing
 * routes MultiMedia1 to both ports).
 *
 * Measured on hardware with the amplifiers' report register (SPKRPTSEL 3,
 * the samples they receive): this ADSP fills a frame only with all 4 slots
 * active, and without a slot mapping (which it rejects for a port alone in
 * its group; stock never sends one) it places stream channels 32 bits
 * apart: channel 0 in slot 0, channel 1 in slot 2. So every amplifier plays
 * the first slot of a pair: pair 0 (slot 0) for the left channel, pair 1
 * (slot 2) for the right. In landscape with the home button on the right
 * (the keyboard cover's orientation) the top speakers are on the left: they
 * play the left channel, the bottom ones the right.
 */
&adsp_pil {
	firmware-name = "qcom/msm8996/samsung/gts3/adsp.mdt";
	status = "okay";
};

/*
 * Sensors
 * -------
 * The motion and light sensors sit on the SLPI's own buses, out of the
 * AP's reach (stock sensor_def_qcomdev.conf): LSM6DS3 accelerometer and
 * gyroscope on SSC SPI (interrupt TLMM 122, owned by the SLPI), AK09916C
 * magnetometer on SSC I2C 3 at 0x0c, CM3323 light sensor on SSC I2C 2 at
 * 0x10. Linux talks to the SLPI's sensor manager: qcom_sns_reg serves it
 * the sensor registry (sns.reg, which Samsung keeps on the efs partition
 * with the factory calibration) and qcom_smgr exposes the sensors as IIO
 * devices. The driver's default mount matrix gives the right orientation
 * for iio-sensor-proxy (checked in all four positions).
 */
&slpi_pil {
	firmware-name = "qcom/msm8996/samsung/gts3/slpi.mdt";
	px-supply = <&vreg_lvs2a_1p8>;
	status = "okay";
};

/*
 * GNSS
 * ----
 * The GNSS engine runs on the modem DSP (MSS, Hexagon QDSP6 v5.5) on both
 * models: the SM-T820 carries a GNSS-only modem image (Product_Flavor
 * "modemlite" in the modem partition's verinfo), the SM-T825 the full LTE
 * one. The MSS has auto_boot off: rmtfs, which serves it the modemst1,
 * modemst2, fsg and fsc partitions, starts it ("rmtfs -s"), and the
 * location service (QMI LOC) is then reached over QRTR. Firmware from the
 * tablet's own modem partition (image/mba.mbn and image/modem.*). PLL
 * supply: PM8994 L12 at 1.8 V, as downstream vdd_pll-supply
 * (msm8996.dtsi qcom,mss@2080000).
 */
&mss_pil {
	firmware-name = "qcom/msm8996/samsung/gts3/mba.mbn",
			"qcom/msm8996/samsung/gts3/modem.mdt";
	pll-supply = <&vreg_l12a_1p8>;
	status = "okay";
};

&slim_msm {
	status = "okay";

	slim@1 {
		reg = <1>;
		#address-cells = <2>;
		#size-cells = <0>;

		tasha_ifd: tas-ifd@0,0 {
			compatible = "slim217,1a0";
			reg = <0 0>;
		};

		wcd9335: codec@1,0 {
			compatible = "slim217,1a0";
			reg = <1 0>;

			clock-names = "mclk", "slimbus";
			clocks = <&div1_mclk>,
				 <&rpmcc RPM_SMD_BB_CLK1>;
			interrupt-parent = <&tlmm>;
			interrupts = <79 IRQ_TYPE_LEVEL_HIGH>;
			interrupt-names = "intr1";
			interrupt-controller;
			#interrupt-cells = <1>;

			pinctrl-0 = <&cdc_reset_active &wcd_intr_default>;
			pinctrl-names = "default";

			reset-gpios = <&tlmm 74 GPIO_ACTIVE_LOW>;
			slim-ifc-dev = <&tasha_ifd>;

			#sound-dai-cells = <1>;

			vdd-buck-supply = <&vreg_s4a_1p8>;
			vdd-buck-sido-supply = <&vreg_s4a_1p8>;
			vdd-tx-supply = <&vreg_s4a_1p8>;
			vdd-rx-supply = <&vreg_s4a_1p8>;
			vdd-io-supply = <&vreg_s4a_1p8>;

			qcom,micbias2-microvolt = <2700000>;

			/*
			 * Both jack switches are normally open (downstream
			 * qcom,msm-mbhc-hphl-swh and -gnd-swh = <1>), so neither
			 * normally-closed property. Buttons: 0 (play), 135
			 * (voice), 240 (volume up) and 470 ohm (volume down) on
			 * the 1.8 V pull up. These are downstream's upper limits
			 * without its first one (13 mV), which it only used to
			 * give play two codes, and with the last ones at 470 mV.
			 * The top one tells headphones from a headset: downstream
			 * has 690 mV, but at 2.7 V. 470 mV is the same 750 ohm.
			 */
			qcom,mbhc-buttons-vthreshold-microvolt = <88000 138000 225000 450000
								  470000 470000 470000 470000>;
		};
	};
};

&q6asmdai {
	dai@0 {
		reg = <MSM_FRONTEND_DAI_MULTIMEDIA1>;
	};

	dai@1 {
		reg = <MSM_FRONTEND_DAI_MULTIMEDIA2>;
	};

	dai@2 {
		reg = <MSM_FRONTEND_DAI_MULTIMEDIA3>;
	};

	dai@3 {
		reg = <MSM_FRONTEND_DAI_MULTIMEDIA4>;
	};
};

&sound {
	compatible = "qcom,apq8096-sndcard";
	model = "Galaxy Tab S3";
	/*
	 * Downstream mic routing: AMIC1 <- MIC BIAS4 (third mic), AMIC2 <-
	 * MIC BIAS2 (headset mic), AMIC3 <- MIC BIAS1 (main mic), AMIC4 <-
	 * MIC BIAS3 (sub mic). In the wcd9335 driver only the RX DACs (via
	 * RX_BIAS) pull in MCLK, so a capture without a playback stream
	 * records digital silence. Hang the mic biases on MCLK as well.
	 */
	pinctrl-0 = <&pri_tdm_clk_default>, <&pri_tdm_data_default>,
		    <&quat_tdm_clk_default>, <&quat_tdm_data_default>;
	pinctrl-names = "default";

	audio-routing = "RX_BIAS", "MCLK",
			"MIC BIAS1", "MCLK",
			"MIC BIAS2", "MCLK",
			"MIC BIAS3", "MCLK",
			"MIC BIAS4", "MCLK",
			"AMIC1", "MIC BIAS4",
			"AMIC2", "MIC BIAS2",
			"AMIC3", "MIC BIAS1",
			"AMIC4", "MIC BIAS3";

	mm1-dai-link {
		link-name = "MultiMedia1";
		cpu {
			sound-dai = <&q6asmdai MSM_FRONTEND_DAI_MULTIMEDIA1>;
		};
	};

	mm2-dai-link {
		link-name = "MultiMedia2";
		cpu {
			sound-dai = <&q6asmdai MSM_FRONTEND_DAI_MULTIMEDIA2>;
		};
	};

	mm3-dai-link {
		link-name = "MultiMedia3";
		cpu {
			sound-dai = <&q6asmdai MSM_FRONTEND_DAI_MULTIMEDIA3>;
		};
	};

	/* The headset mic, its own stream so it never reopens the built-in mics */
	mm4-dai-link {
		link-name = "MultiMedia4";
		cpu {
			sound-dai = <&q6asmdai MSM_FRONTEND_DAI_MULTIMEDIA4>;
		};
	};

	slim-dai-link {
		link-name = "SLIM Playback";
		cpu {
			sound-dai = <&q6afedai SLIMBUS_6_RX>;
		};

		platform {
			sound-dai = <&q6routing>;
		};

		codec {
			sound-dai = <&wcd9335 AIF4_PB>;
		};
	};

	slimcap-dai-link {
		link-name = "SLIM Capture";
		cpu {
			sound-dai = <&q6afedai SLIMBUS_0_TX>;
		};

		platform {
			sound-dai = <&q6routing>;
		};

		codec {
			sound-dai = <&wcd9335 AIF1_CAP>;
		};
	};

	slimcap-headset-dai-link {
		link-name = "SLIM Headset Capture";
		cpu {
			sound-dai = <&q6afedai SLIMBUS_1_TX>;
		};

		platform {
			sound-dai = <&q6routing>;
		};

		codec {
			sound-dai = <&wcd9335 AIF2_CAP>;
		};
	};

	spk-bottom-dai-link {
		link-name = "Speaker Bottom Playback";
		cpu {
			sound-dai = <&q6afedai PRIMARY_TDM_RX_0>;
		};

		platform {
			sound-dai = <&q6routing>;
		};

		codec {
			sound-dai = <&spk_bottom1>, <&spk_bottom2>;
		};
	};

	spk-top-dai-link {
		link-name = "Speaker Top Playback";
		cpu {
			sound-dai = <&q6afedai QUATERNARY_TDM_RX_0>;
		};

		platform {
			sound-dai = <&q6routing>;
		};

		codec {
			sound-dai = <&spk_top1>, <&spk_top2>;
		};
	};
};

&q6afedai {
	dai@24 {
		reg = <PRIMARY_TDM_RX_0>;
		qcom,tdm-sync-mode = <1>;
		qcom,tdm-sync-src = <1>;
		qcom,tdm-data-out = <0>;
		qcom,tdm-invert-sync = <1>;
		qcom,tdm-data-delay = <1>;
		qcom,tdm-data-align = <0>;
	};

	dai@72 {
		reg = <QUATERNARY_TDM_RX_0>;
		qcom,tdm-sync-mode = <1>;
		qcom,tdm-sync-src = <1>;
		qcom,tdm-data-out = <0>;
		qcom,tdm-invert-sync = <1>;
		qcom,tdm-data-delay = <1>;
		qcom,tdm-data-align = <0>;
	};
};

&blsp1_i2c3 {
	clock-frequency = <400000>;
	status = "okay";

	spk_top2: amplifier@34 {
		compatible = "richtek,rt5508";
		reg = <0x34>;
		#sound-dai-cells = <0>;
		sound-name-prefix = "Top 2";
		richtek,channel-select = <0>;
		richtek,tdm-dac-slot = <0>;
	};

	spk_top1: amplifier@35 {
		compatible = "richtek,rt5508";
		reg = <0x35>;
		#sound-dai-cells = <0>;
		sound-name-prefix = "Top 1";
		richtek,channel-select = <0>;
		richtek,tdm-dac-slot = <0>;
	};

	spk_bottom2: amplifier@36 {
		compatible = "richtek,rt5508";
		reg = <0x36>;
		#sound-dai-cells = <0>;
		sound-name-prefix = "Bottom 2";
		richtek,channel-select = <0>;
		richtek,tdm-dac-slot = <1>;
	};

	spk_bottom1: amplifier@37 {
		compatible = "richtek,rt5508";
		reg = <0x37>;
		#sound-dai-cells = <0>;
		sound-name-prefix = "Bottom 1";
		richtek,channel-select = <0>;
		richtek,tdm-dac-slot = <1>;
	};
};

/*
 * SM5705 fuel gauge on TLMM 6 (SDA) / 7 (SCL). Downstream bit-bangs
 * these too, but they are the BLSP2 QUP2 I2C pins, so use the controller.
 * Its alert line (PM8994 GPIO 1) is not used; the driver polls.
 */
/*
 * Rear camera lens: Dongwoon DW9807 voice coil driver, downstream
 * actuator@18 on i2c_7. The module's calibration EEPROM shares the bus at
 * 0x58 (downstream eeprom@50, 0x1200 bytes, 16-bit addressing); it has
 * no binding yet.
 */
&blsp2_i2c1 {
	clock-frequency = <400000>;
	status = "okay";

	rear_lens: camera-lens@c {
		compatible = "dongwoon,dw9807-vcm";
		reg = <0x0c>;

		vdd-supply = <&vreg_l17a_2p8>;
		vio-supply = <&vreg_lvs1a_1p8>;
	};
};

&blsp2_i2c2 {
	clock-frequency = <100000>;
	status = "okay";

	fuel-gauge@71 {
		compatible = "siliconmitus,sm5705-fuel-gauge";
		reg = <0x71>;
		monitored-battery = <&battery>;
		power-supplies = <&charger>;
	};
};

/* Touchscreen: Synaptics S5807 (RMI4), downstream tsp on i2c_9 */
&blsp2_i2c3 {
	status = "okay";

	touchscreen@20 {
		compatible = "syna,rmi4-i2c";
		reg = <0x20>;
		#address-cells = <1>;
		#size-cells = <0>;

		interrupt-parent = <&tlmm>;
		interrupts = <123 IRQ_TYPE_LEVEL_LOW>;

		vdd-supply = <&vreg_l18a_3p3>;
		vio-supply = <&vreg_l14a_1p8>;

		pinctrl-names = "default";
		pinctrl-0 = <&ts_int_default>;

		syna,startup-delay-ms = <100>;

		rmi4-f01@1 {
			reg = <0x1>;
			syna,nosleep-mode = <1>;
		};

		rmi4-f12@12 {
			reg = <0x12>;
			syna,sensor-type = <1>;
			/*
			 * The sensor reports 1536 x 2048 in the portrait frame.
			 * Map it to the panel's 2048 x 1536 landscape frame, as
			 * DRM expects: panel (x, y) = (y, 1535 - x). RMI4 inverts
			 * first, then swaps (docs/input.md).
			 */
			touchscreen-inverted-x;
			touchscreen-swapped-x-y;
			/* The panel's active area in the sensor's own frame */
			touchscreen-x-mm = <147>;
			touchscreen-y-mm = <196>;
		};
	};
};

/*
 * S-Pen: Wacom W9019 with Samsung firmware, downstream wacom@56 on i2c_12.
 * The interrupt (TLMM 34) is falling-edge in stock, but the line stays low
 * until the packet is read, so level-low here. Flash mode (TLMM 24) is held
 * low to run the firmware. Stock flips x and then swaps x/y into portrait,
 * so in the panel's landscape frame both axes are inverted and nothing is
 * swapped.
 */
&blsp2_i2c6 {
	clock-frequency = <400000>;
	status = "okay";

	digitizer@56 {
		compatible = "wacom,w9019";
		reg = <0x56>;

		interrupt-parent = <&tlmm>;
		interrupts = <34 IRQ_TYPE_LEVEL_LOW>;

		vdd-supply = <&pen_vdd>;
		flash-mode-gpios = <&tlmm 24 GPIO_ACTIVE_HIGH>;

		pinctrl-names = "default";
		pinctrl-0 = <&pen_int_default &pen_flash_default>;

		touchscreen-x-mm = <196>;
		touchscreen-y-mm = <147>;
		touchscreen-inverted-x;
		touchscreen-inverted-y;
	};
};

/*
 * Cameras (downstream msm8996-camera-sensor-gts3llte-r00.dtsi):
 *   rear:  Sony IMX258, CCI master 0, CSIPHY0, 4 lanes, MCLK0,
 *          reset TLMM 30, mount angle 90
 *   front: Samsung S5K5E3, CCI master 1, CSIPHY2, 2 lanes, MCLK2,
 *          reset TLMM 40, mount angle 270
 * Both take a 24 MHz MCLK.
 */
&camss {
	vdda-supply = <&vreg_l2a_1p25>;

	status = "okay";

	ports {
		port@0 {
			reg = <0>;

			csiphy0_ep: endpoint {
				clock-lanes = <7>;
				data-lanes = <0 1 2 3>;
				remote-endpoint = <&rear_camera_ep>;
			};
		};

		port@2 {
			reg = <2>;

			csiphy2_ep: endpoint {
				clock-lanes = <7>;
				data-lanes = <0 1>;
				remote-endpoint = <&front_camera_ep>;
			};
		};
	};
};

&cci {
	status = "okay";
};

&cci_i2c0 {
	clock-frequency = <1000000>;

	camera@1a {
		compatible = "sony,imx258";
		reg = <0x1a>;

		clocks = <&mmcc CAMSS_MCLK0_CLK>;
		assigned-clocks = <&mmcc CAMSS_MCLK0_CLK>;
		assigned-clock-rates = <24000000>;

		reset-gpios = <&tlmm 30 GPIO_ACTIVE_LOW>;

		vana-supply = <&vreg_l29a_2p8>;
		vdig-supply = <&cam_rear_vdig>;
		vif-supply = <&vreg_lvs1a_1p8>;

		pinctrl-names = "default";
		pinctrl-0 = <&cam_rear_default>;

		orientation = <1>;
		rotation = <0>;
		lens-focus = <&rear_lens>;

		port {
			rear_camera_ep: endpoint {
				data-lanes = <1 2 3 4>;
				link-frequencies = /bits/ 64 <636000000 321000000>;
				remote-endpoint = <&csiphy0_ep>;
			};
		};
	};
};

&cci_i2c1 {
	clock-frequency = <1000000>;

	camera@10 {
		compatible = "samsung,s5k5e3";
		reg = <0x10>;

		clocks = <&mmcc CAMSS_MCLK2_CLK>;
		assigned-clocks = <&mmcc CAMSS_MCLK2_CLK>;
		assigned-clock-rates = <24000000>;

		reset-gpios = <&tlmm 40 GPIO_ACTIVE_LOW>;

		vdda-supply = <&vreg_l23a_2p8>;
		vddd-supply = <&cam_front_vdig>;
		vddio-supply = <&vreg_lvs1a_1p8>;

		pinctrl-names = "default";
		pinctrl-0 = <&cam_front_default>;

		orientation = <0>;
		rotation = <0>;

		port {
			front_camera_ep: endpoint {
				data-lanes = <1 2>;
				link-frequencies = /bits/ 64 <448000000>;
				remote-endpoint = <&csiphy2_ep>;
			};
		};
	};
};

&pm8994_gpios {
	pinctrl-0 = <&usb3_redriver_en>;
	pinctrl-names = "default";

	/* Home: digital input, no pull (external pull-up), 1.8 V */
	home_key_default: home-key-default-state {
		pins = "gpio2";
		function = PMIC_GPIO_FUNC_NORMAL;
		input-enable;
		bias-disable;
		power-source = <PM8994_GPIO_S4>;
	};

	/* Volume Up: digital input, 30 uA pull-up, 1.8 V */
	vol_up_default: vol-up-default-state {
		pins = "gpio3";
		function = PMIC_GPIO_FUNC_NORMAL;
		input-enable;
		bias-pull-up;
		qcom,pull-up-strength = <PMIC_GPIO_PULL_UP_30>;
		power-source = <PM8994_GPIO_S4>;
	};

	/* MUIC interrupt: push-pull 1.8 V output, idle high */
	muic_int_default: muic-int-default-state {
		pins = "gpio4";
		function = PMIC_GPIO_FUNC_NORMAL;
		input-enable;
		bias-pull-down;
		power-source = <PM8994_GPIO_S4>;
	};

	wlan_en_default: wlan-en-state {
		pins = "gpio8";
		function = PMIC_GPIO_FUNC_NORMAL;
		output-low;
		qcom,drive-strength = <PMIC_GPIO_STRENGTH_LOW>;
		power-source = <PM8994_GPIO_S4>;
		bias-disable;
	};

	rome_enable_default: rome-enable-state {
		pins = "gpio9";
		function = PMIC_GPIO_FUNC_NORMAL;
		output-low;
		qcom,drive-strength = <PMIC_GPIO_STRENGTH_LOW>;
		power-source = <PM8994_GPIO_S4>;
		bias-disable;
	};

	/*
	 * USB 3.0 redriver enable, kept on. Its supply defaults to VPH_PWR:
	 * use S4 (1.8 V), as Samsung's DT does, before it goes high.
	 */
	usb3_redriver_en: usb3-redriver-en-state {
		pins = "gpio14";
		function = PMIC_GPIO_FUNC_NORMAL;
		output-high;
		bias-disable;
		power-source = <PM8994_GPIO_S4>;
	};

	audio_mclk_default: audio-mclk-state {
		pins = "gpio15";
		function = PMIC_GPIO_FUNC_FUNC1;
		bias-disable;
		power-source = <PM8994_GPIO_S4>;
		qcom,drive-strength = <PMIC_GPIO_STRENGTH_LOW>;
	};

	rome_sleep_clk_default: rome-sleep-clk-state {
		pins = "gpio18";
		function = PMIC_GPIO_FUNC_FUNC2;
		bias-disable;
		power-source = <PM8994_GPIO_S4>;
	};

	bt_en_default: bt-en-state {
		pins = "gpio19";
		function = PMIC_GPIO_FUNC_NORMAL;
		output-low;
		qcom,drive-strength = <PMIC_GPIO_STRENGTH_LOW>;
		power-source = <PM8994_GPIO_S4>;
		bias-pull-down;
	};
};

&tlmm {
	/*
	 * Pins owned by Samsung's TrustZone. If Linux reads them, the firmware
	 * resets the tablet about 9 s into boot (confirmed on hardware).
	 *   25-28: BLSP1 QUP6 SPI, fingerprint sensor (downstream spi_6 / etspi)
	 * 58-61 (BLSP2 QUP4 SPI, the eSE SPI in the downstream pinctrl) are
	 * free on the Wi-Fi model: stock comments its eSE node out, and they
	 * carry the quaternary TDM bus to the top speakers.
	 */
	gpio-reserved-ranges = <25 4>;

	tkey_i2c_default: tkey-i2c-default-state {
		pins = "gpio21", "gpio22";
		function = "gpio";
		drive-strength = <2>;
		bias-disable;
	};

	tkey_int_default: tkey-int-default-state {
		pins = "gpio64";
		function = "gpio";
		drive-strength = <2>;
		bias-disable;
	};

	tkey_led_en_default: tkey-led-en-default-state {
		pins = "gpio118";
		function = "gpio";
		drive-strength = <2>;
		bias-disable;
	};

	sm5705_i2c_default: sm5705-i2c-default-state {
		pins = "gpio32", "gpio33";
		function = "gpio";
		drive-strength = <2>;
		bias-disable;
	};

	charger_int_default: charger-int-default-state {
		pins = "gpio38";
		function = "gpio";
		drive-strength = <2>;
		bias-pull-up;
	};

	/* LCD_LDO_EN, from downstream mdss_dsi_active (gpio46) */
	lcd_ldo_en_default: lcd-ldo-en-default-state {
		pins = "gpio46";
		function = "gpio";
		drive-strength = <8>;
		bias-disable;
	};

	quat_tdm_clk_default: quat-tdm-clk-default-state {
		pins = "gpio58", "gpio59";
		function = "qua_mi2s";
		drive-strength = <8>;
		bias-disable;
	};

	quat_tdm_data_default: quat-tdm-data-default-state {
		pins = "gpio61";
		function = "qua_mi2s";
		drive-strength = <8>;
		bias-pull-down;
	};

	pri_tdm_clk_default: pri-tdm-clk-default-state {
		pins = "gpio65", "gpio66";
		function = "pri_mi2s";
		drive-strength = <8>;
		bias-disable;
	};

	pri_tdm_data_default: pri-tdm-data-default-state {
		pins = "gpio67", "gpio68";
		function = "pri_mi2s";
		drive-strength = <8>;
		bias-pull-down;
	};

	s2mm005_int_default: s2mm005-int-default-state {
		pins = "gpio73";
		function = "gpio";
		drive-strength = <2>;
		bias-disable;
		input-enable;
	};

	cdc_reset_active: cdc-reset-active-state {
		pins = "gpio74";
		function = "gpio";
		drive-strength = <16>;
		/delete-property/ bias-pull-down;
		bias-disable;
		output-high;
	};

	wcd_intr_default: wcd-intr-default-state {
		pins = "gpio79";
		function = "gpio";
		drive-strength = <2>;
		bias-pull-down;
		input-enable;
	};

	blsp1_i2c5_default: blsp1-i2c5-default-state {
		pins = "gpio83", "gpio84";
		function = "blsp_i2c5";
		drive-strength = <6>;
		bias-disable;
	};

	blsp1_i2c5_sleep: blsp1-i2c5-sleep-state {
		pins = "gpio83", "gpio84";
		function = "gpio";
		drive-strength = <2>;
		bias-disable;
	};

	/* Panel TE, downstream mdss_te_active */
	mdss_te_default: mdss-te-default-state {
		pins = "gpio10";
		function = "mdp_vsync";
		drive-strength = <2>;
		bias-pull-down;
	};

	mdss_te_sleep: mdss-te-sleep-state {
		pins = "gpio10";
		function = "mdp_vsync";
		drive-strength = <2>;
		bias-pull-down;
	};

	/* Panel reset (143) and TCON_RDY (45), downstream mdss_dsi_active / tcon_rdy_active */
	panel_default: panel-default-state {
		reset-pins {
			pins = "gpio143";
			function = "gpio";
			drive-strength = <8>;
			bias-disable;
		};

		tcon-ready-pins {
			pins = "gpio45";
			function = "gpio";
			drive-strength = <2>;
			bias-pull-down;
		};
	};

	/* Touch interrupt, downstream tsp_int_active */
	ts_int_default: ts-int-default-state {
		pins = "gpio123";
		function = "gpio";
		drive-strength = <2>;
		bias-disable;
	};

	pen_int_default: pen-int-default-state {
		pins = "gpio34";
		function = "gpio";
		drive-strength = <2>;
		bias-disable;
	};

	pen_flash_default: pen-flash-default-state {
		pins = "gpio24";
		function = "gpio";
		drive-strength = <2>;
		bias-pull-down;
	};

	pen_vdd_default: pen-vdd-default-state {
		pins = "gpio126";
		function = "gpio";
		drive-strength = <2>;
		bias-disable;
	};

	/* microSD card detect, downstream sdc2_cd_on */
	sdc2_cd_default: sdc2-cd-default-state {
		pins = "gpio95";
		function = "gpio";
		drive-strength = <2>;
		bias-disable;
	};

	cam_rear_default: cam-rear-default-state {
		mclk-pins {
			pins = "gpio13";
			function = "cam_mclk";
			drive-strength = <4>;
			bias-disable;
		};

		reset-pins {
			pins = "gpio30";
			function = "gpio";
			drive-strength = <2>;
			bias-disable;
		};
	};

	cam_rear_vdig_en_default: cam-rear-vdig-en-state {
		pins = "gpio9";
		function = "gpio";
		drive-strength = <2>;
		bias-disable;
	};

	cam_front_default: cam-front-default-state {
		mclk-pins {
			pins = "gpio15";
			function = "cam_mclk";
			drive-strength = <4>;
			bias-disable;
		};

		reset-pins {
			pins = "gpio40";
			function = "gpio";
			drive-strength = <2>;
			bias-disable;
		};
	};

	cam_front_vdig_en_default: cam-front-vdig-en-state {
		pins = "gpio8";
		function = "gpio";
		drive-strength = <2>;
		bias-disable;
	};

	pogo_i2c_default: pogo-i2c-default-state {
		pins = "gpio2", "gpio3";
		function = "gpio";
		drive-strength = <8>;
		bias-disable;
	};

	pogo_kbd_int_default: pogo-kbd-int-default-state {
		pins = "gpio54";
		function = "gpio";
		drive-strength = <8>;
		bias-pull-up;
	};
};
